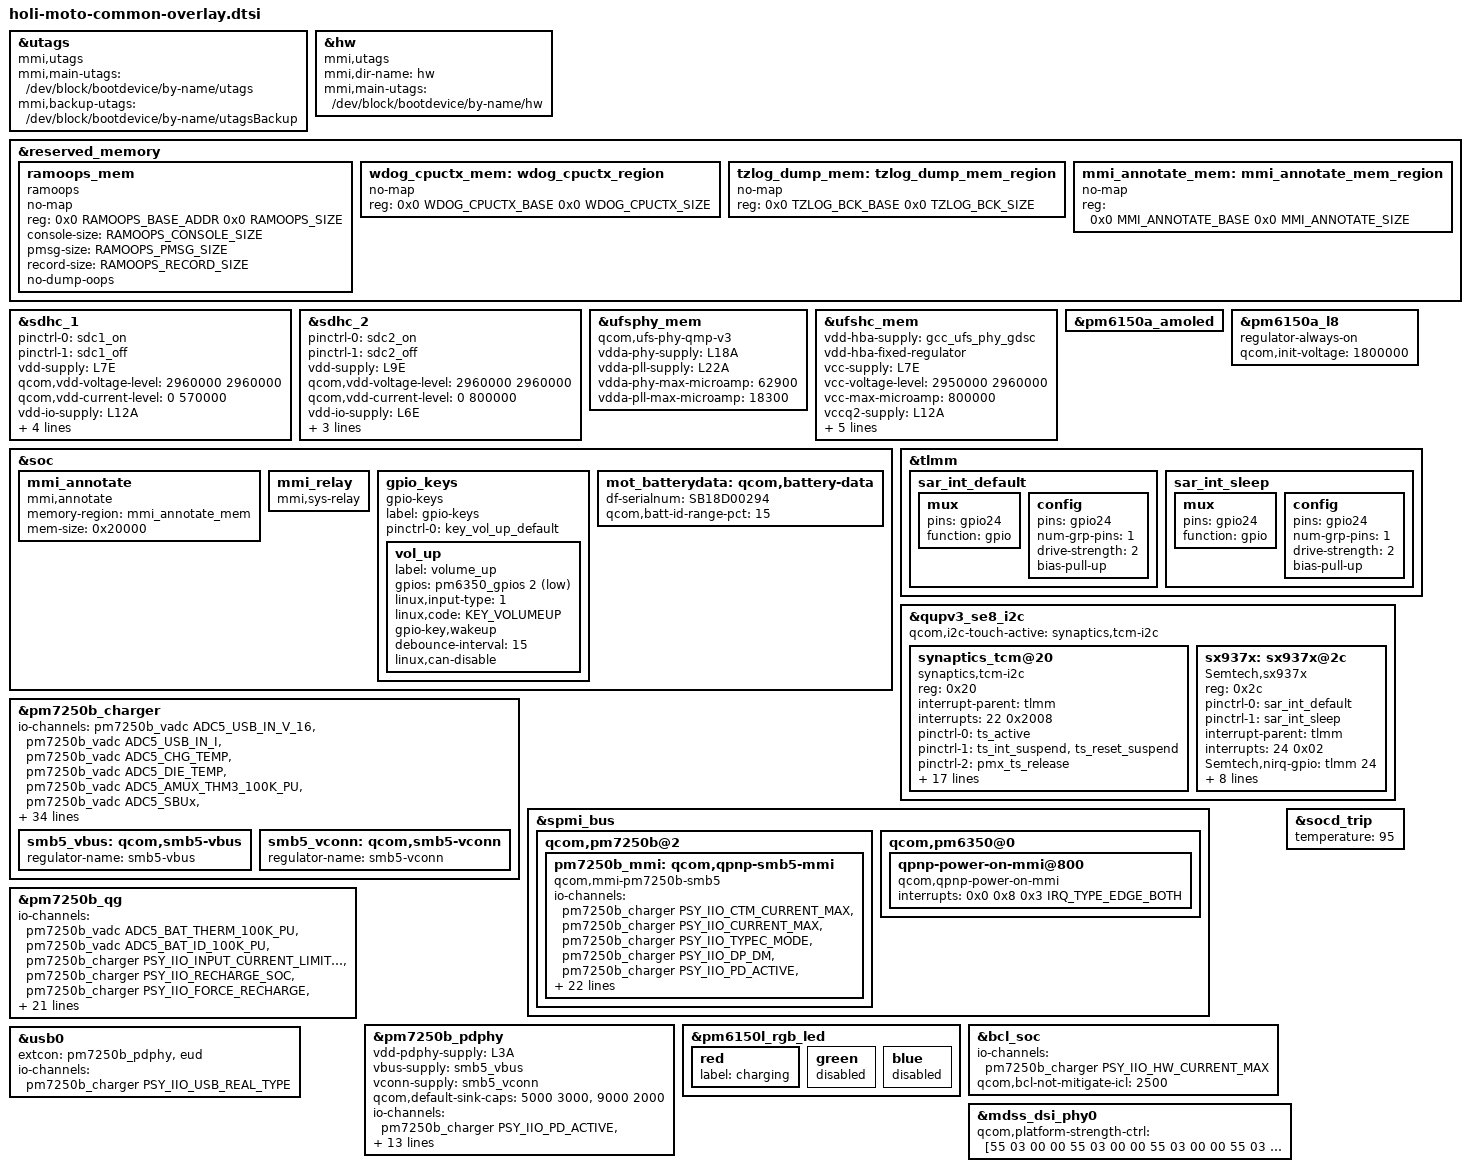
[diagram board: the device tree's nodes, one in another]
/* Copyright (c) 2020, The Linux Foundation. All rights reserved.
 *
 * This program is free software; you can redistribute it and/or modify
 * it under the terms of the GNU General Public License version 2 and
 * only version 2 as published by the Free Software Foundation.
 *
 * This program is distributed in the hope that it will be useful,
 * but WITHOUT ANY WARRANTY; without even the implied warranty of
 * MERCHANTABILITY or FITNESS FOR A PARTICULAR PURPOSE.  See the
 * GNU General Public License for more details.
 */

#include <dt-bindings/gpio/gpio.h>
#include <dt-bindings/input/linux-event-codes.h>
#include "carrier-channel-ids.dtsi"

#include "holi-pmic-overlay.dtsi"
#include "display/holi-sde-display-mtp.dtsi"
#include "holi-thermal-overlay.dtsi"
#include <dt-bindings/iio/qti_power_supply_iio.h>
#include <dt-bindings/moto/moto-mem-reserve.h>

&utags {
	compatible = "mmi,utags";
	mmi,main-utags = "/dev/block/bootdevice/by-name/utags";
	mmi,backup-utags = "/dev/block/bootdevice/by-name/utagsBackup";
};

&hw {
	compatible = "mmi,utags";
	mmi,dir-name = "hw";
	mmi,main-utags = "/dev/block/bootdevice/by-name/hw";
};

&reserved_memory {
	ramoops_mem {
		compatible = "ramoops";
		no-map;
		reg = <0x0 RAMOOPS_BASE_ADDR 0x0 RAMOOPS_SIZE>;
		console-size = <RAMOOPS_CONSOLE_SIZE>;
		pmsg-size = <RAMOOPS_PMSG_SIZE>;
		record-size = <RAMOOPS_RECORD_SIZE>;
		no-dump-oops;
	};

	wdog_cpuctx_mem: wdog_cpuctx_region {
		no-map;
		reg = <0x0 WDOG_CPUCTX_BASE
				0x0 WDOG_CPUCTX_SIZE>;
	};

	tzlog_dump_mem: tzlog_dump_mem_region {
		no-map;
		reg = <0x0  TZLOG_BCK_BASE
				0x0 TZLOG_BCK_SIZE>;
	};

	mmi_annotate_mem: mmi_annotate_mem_region {
		no-map;
		reg = <0x0  MMI_ANNOTATE_BASE
				0x0 MMI_ANNOTATE_SIZE>;
	};
};

&sdhc_1 {
	status = "ok";

	pinctrl-names = "default", "sleep";
	pinctrl-0 = <&sdc1_on>;
	pinctrl-1 = <&sdc1_off>;

	vdd-supply = <&L7E>;
	qcom,vdd-voltage-level = <2960000 2960000>;
	qcom,vdd-current-level = <0 570000>;

	vdd-io-supply = <&L12A>;
	qcom,vdd-io-always-on;
	qcom,vdd-io-lpm-sup;
	qcom,vdd-io-voltage-level = <1800000 1800000>;
	qcom,vdd-io-current-level = <0 325000>;
};

&sdhc_2 {
	status = "ok";

	pinctrl-names = "default", "sleep";
	pinctrl-0 = <&sdc2_on>;
	pinctrl-1 = <&sdc2_off>;

	vdd-supply = <&L9E>;
	qcom,vdd-voltage-level = <2960000 2960000>;
	qcom,vdd-current-level = <0 800000>;

	vdd-io-supply = <&L6E>;
	qcom,vdd-io-voltage-level = <1800000 2960000>;
	qcom,vdd-io-current-level = <0 22000>;

	cd-gpios = <&tlmm 94 GPIO_ACTIVE_LOW>;
};

&ufsphy_mem {
		compatible = "qcom,ufs-phy-qmp-v3";

		vdda-phy-supply = <&L18A>;
		vdda-pll-supply = <&L22A>;
		vdda-phy-max-microamp = <62900>;
		vdda-pll-max-microamp = <18300>;

		status = "ok";
};

&ufshc_mem {
		vdd-hba-supply = <&gcc_ufs_phy_gdsc>;
		vdd-hba-fixed-regulator;

		vcc-supply = <&L7E>;
		vcc-voltage-level = <2950000 2960000>;
		vcc-max-microamp = <800000>;

		vccq2-supply = <&L12A>;
		vccq2-max-microamp = <800000>;
		vccq2-voltage-level = <1800000 1800000>;

		qcom,vddp-ref-clk-supply = <&L22A>;
		qcom,vddp-ref-clk-max-microamp = <100>;

		status = "ok";
};

&soc {
	mmi_annotate {
		compatible = "mmi,annotate";
		memory-region = <&mmi_annotate_mem>;
		mem-size = <0x20000>;
	};

	mmi_relay{
		compatible = "mmi,sys-relay";
	};

	gpio_keys: gpio_keys {
		compatible = "gpio-keys";
		label = "gpio-keys";

		pinctrl-names = "default";
		pinctrl-0 = <&key_vol_up_default>;

		vol_up {
			label = "volume_up";
			gpios = <&pm6350_gpios 2 GPIO_ACTIVE_LOW>;
			linux,input-type = <1>;
			linux,code = <KEY_VOLUMEUP>;
			gpio-key,wakeup;
			debounce-interval = <15>;
			linux,can-disable;
		};
	};

	mot_batterydata: qcom,battery-data {
		df-serialnum = "SB18D00294";
		qcom,batt-id-range-pct = <15>;
		#include "qg-batterydata-md50-amperex-5000mah.dtsi"
	};
};

&pm6150a_amoled {
	status = "ok";
};

&pm6150a_l8 {
	regulator-always-on;
	qcom,init-voltage = <1800000>;
};

&tlmm {
	sar_int_default: sar_int_default {
			mux {
				pins = "gpio24";
				function =  "gpio";
			};
			config {
				pins = "gpio24";
				num-grp-pins = <1>;
				drive-strength = <2>;
				bias-pull-up;
			};
	};

	sar_int_sleep: sar_int_sleep {
			mux {
				pins = "gpio24";
				function =  "gpio";
			};
			config {
				pins = "gpio24";
				num-grp-pins = <1>;
				drive-strength = <2>;
				bias-pull-up;
			};
	};
};

&qupv3_se8_i2c {
	status = "okay";
	qcom,i2c-touch-active="synaptics,tcm-i2c";

	synaptics_tcm@20 {
		compatible = "synaptics,tcm-i2c";
		reg = <0x20>;
		interrupt-parent = <&tlmm>;
		interrupts = <22 0x2008>;
		pinctrl-names = "pmx_ts_active","pmx_ts_suspend",
					"pmx_ts_release";
		pinctrl-0 = <&ts_active>;
		pinctrl-1 = <&ts_int_suspend &ts_reset_suspend>;
		pinctrl-2 = <&pmx_ts_release>;
		vdd-supply = <&L11A>;
		avdd-supply = <&L6A>;
		synaptics,pwr-reg-name = "avdd";
		synaptics,bus-reg-name = "vdd";
		synaptics,irq-gpio = <&tlmm 22 0x2008>;
		synaptics,irq-on-state = <0>;
		synaptics,reset-gpio = <&tlmm 21 0x00>;
		synaptics,reset-on-state = <0>;
		synaptics,reset-active-ms = <20>;
		synaptics,reset-delay-ms = <200>;
		synaptics,power-delay-ms = <200>;
		synaptics,ubl-i2c-addr = <0x20>;
		synaptics,extend_report;
		synaptics,firmware-name = "synaptics_firmware.img";

		panel = <&dsi_rm69299_visionox_amoled_video
			&dsi_rm69299_visionox_amoled_cmd>;
	};

	sx937x:sx937x@2c {
		compatible = "Semtech,sx937x";
		reg = <0x2c>;
		pinctrl-names = "default","sleep";
		pinctrl-0 = <&sar_int_default>;
		pinctrl-1 = <&sar_int_sleep>;
		interrupt-parent = <&tlmm>;
		interrupts = <24 0x02>;
		interrupt-names = "sx937x_irq";
		Semtech,nirq-gpio = <&tlmm 24 0x02>;
		cap_vdd-supply = <&pm6150a_l8>;
		/*use PH4/5/6 as the reference sensor
		set it to 0xff if the ref-phases-x is not used*/
		Semtech,ref-phases-a = <4>;
		Semtech,ref-phases-b = <5>;
		Semtech,ref-phases-c = <6>;
		Semtech,button-flag = <0x0f>;
		Semtech,reg-num = <61>;
		Semtech,reg-init = <
			0x8024  0x7F00 		/*PHEN, Disable all Phases*/
			0x4004  0x74 		/*irq mask*/
			0x8020  0x10 		/*Set scan period*/

			/*set Phase sampling frequency to 65KHz*/
			0x8028  0x876 		/*AFE_PARAM_PH0*/
			0x8034  0x876 		/*AFE_PARAM_PH1*/
			0x8040  0x876 		/*AFE_PARAM_PH2*/
			0x804C  0x876    	/*AFE_PARAM_PH3*/
			0x8058  0x876 		/*AFE_PARAM_PH4*/
			0x8064  0x876 		/*AFE_PARAM_PH5*/
			0x8070  0x876 		/*AFE_PARAM_PH6*/
			/*0x807C  0x876 */	/*AFE_PARAM_PH7*/

			/*set CS3 to hiz, because it used as IRQ pin*/
			0x8030  0xFFD9FF 	/*REG_AFEPH_PH0, CS4, ANT1, Bottom*/
			0x803C  0xBFF9FF 	/*REG_AFEPH_PH1, CS7, ANT2, Top Right*/
			0x8048  0xFFF9FD 	/*REG_AFEPH_PH2, CS0, ANT3, Top Left*/
			0x8054  0xFEF9FF	/*REG_AFEPH_PH3, CS5, ANT4, Top Right side*/
			0x8060  0xF7F9FF 	/*REG_AFEPH_PH4, CS6, ANT1_REF, Bottom*/
			0x806C  0xFFF97F 	/*REG_AFEPH_PH5, CS2, ANT2_REF, Top Right*/
			0x8078  0xFFF9EF 	/*REG_AFEPH_PH6, CS1, ANT3_REF, Top Left*/
			0x8084  0xBFF9FF 	/*REG_AFEPH_PH7, NOT USE*/

			/*Set Phase Proximity Threshold*/
			0x8098  0x00009240		/*prox threshold ph0*/
			0x80B8  0x00008035		/*prox threshold ph1*/
			0x80D8  0x00004343		/*prox threshold ph2*/
			0x80F8  0x00003C3C		/*prox threshold ph3*/
			0x8118  0x00000000		/*prox threshold ph4*/
			0x8138  0x00000000		/*prox threshold ph5*/
			0x8158  0x00000000		/*prox threshold ph6*/
			/*0x8178 0x00000000*/	/*prox threshold ph7*/

			/*Set Useful Filter*/
			0x808C  0x20600019		/*PH0 Filter Setup B, non-detect threshold of USE filter*/
			0x80AC  0x20600019		/*PH1 Filter Setup B, non-detect threshold of USE filter*/
			0x80CC  0x20600019		/*PH2 Filter Setup B, non-detect threshold of USE filter*/
			0x80EC  0x20600019		/*PH3 Filter Setup B, non-detect threshold of USE filter*/
			0x810C  0x20600019		/*PH4 Filter Setup B, non-detect threshold of USE filter*/
			0x812C  0x20600019		/*PH5 Filter Setup B, non-detect threshold of USE filter*/
			0x814C  0x20600019		/*PH6 Filter Setup B, non-detect threshold of USE filter*/
			0x816C  0x20600019		/*PH7 Filter Setup B, non-detect threshold of USE filter*/

			0x8090  0x50D47000
			0x80B0  0x46D87000
			0x80D0  0x46D07000
			0x80F0  0x3CDE7000
			0x8110  0x50D27000
			0x8130  0x50D27000
			0x8150  0x50D27000
			0x8170  0x50D27000

			/*PH0123 raw filter 1/4*/
			0x8088  0x300000
			0x80A8  0x300000
			0x80C8  0x300000
			0x80E8  0x300000

			/*PH456 raw filter 1/64*/
			0x8108  0x600000
			0x8128  0x600000
			0x8148  0x600000

			/*Set Reference Phase*/
			0x8188  0x8000014		/*Reference Correction Setup B ENG1*/
			0x818C  0x0				/*Reference Correction Setup B ENG2*/
			0x8190  0x0				/*Reference Correction Setup B ENG3*/
			0x8194  0x0				/*Reference Correction Setup B ENG4*/

			/*Set Reference Correction*/
			0x80A0  0x222200E1      /*Reference Correction Setup A PH0*/
			0x80C0  0x0				/*Reference Correction Setup A PH1*/
			0x80E0  0x0				/*Reference Correction Setup A PH2*/
			0x8100  0x0				/*Reference Correction Setup A PH3*/
			0x8120  0x0				/*Reference Correction Setup A PH4*/
			0x8140  0x0				/*Reference Correction Setup A PH5*/
			0x8160  0x0				/*Reference Correction Setup A PH6*/
			0x8180  0x0				/*Reference Correction Setup A PH7*/

			0x8024  0x7F7F 	/*PHEN, Enable PH0~PH6*/
		>;

		status = "ok";
	};
};

&pm7250b_charger {
	status = "ok";
	#io-channel-cells = <1>;
	io-channels = <&pm7250b_vadc ADC5_USB_IN_V_16>,
		      <&pm7250b_vadc ADC5_USB_IN_I>,
		      <&pm7250b_vadc ADC5_CHG_TEMP>,
		      <&pm7250b_vadc ADC5_DIE_TEMP>,
		      <&pm7250b_vadc ADC5_AMUX_THM3_100K_PU>,
		      <&pm7250b_vadc ADC5_SBUx>,
		      <&pm7250b_vadc ADC5_VPH_PWR>,
		      <&pm7250b_vadc ADC5_AMUX_THM1_100K_PU>,
		      <&pm7250b_qg PSY_IIO_RESISTANCE_ID>,
		      <&pm7250b_qg PSY_IIO_VOLTAGE_NOW>,
		      <&pm7250b_qg PSY_IIO_TEMP>,
		      <&pm7250b_qg PSY_IIO_CAPACITY>,
		      <&pm7250b_qg PSY_IIO_VOLTAGE_OCV>,
		      <&pm7250b_qg PSY_IIO_VOLTAGE_AVG>,
		      <&pm7250b_qg PSY_IIO_DEBUG_BATTERY>,
		      <&pm7250b_qg PSY_IIO_REAL_CAPACITY>,
		      <&pm7250b_qg PSY_IIO_CC_SOC>,
		      <&pm7250b_qg PSY_IIO_CURRENT_NOW>,
		      <&pm7250b_qg PSY_IIO_VOLTAGE_MAX>,
		      <&pm7250b_qg PSY_IIO_CHARGE_FULL>,
		      <&pm7250b_qg PSY_IIO_CHARGE_COUNTER>,
		      <&pm7250b_qg PSY_IIO_CYCLE_COUNT>,
		      <&pm7250b_qg PSY_IIO_CHARGE_FULL_DESIGN>,
		      <&pm7250b_qg PSY_IIO_TIME_TO_FULL_NOW>;
	io-channel-names = "usb_in_voltage",
			   "usb_in_current",
			   "chg_temp",
			   "die_temp",
			   "conn_temp",
			   "sbux_res",
			   "vph_voltage",
			   "skin_temp",
			   "resistance_id",
			   "voltage_now",
			   "temp",
			   "capacity",
			   "voltage_ocv",
			   "voltage_avg",
			   "debug_battery",
			   "real_capacity",
			   "cc_soc",
			   "current_now",
			   "voltage_max",
			   "charge_full",
			   "charge_counter",
			   "cycle_count",
			   "charge_full_design",
			   "time_to_full_now";
	qcom,battery-data = <&mot_batterydata>;
	qcom,sec-charger-config = <0>;
	qcom,auto-recharge-soc = <98>;
	qcom,charger-temp-max = <800>;
	qcom,smb-temp-max = <800>;
	qcom,suspend-input-on-debug-batt;
	qcom,hvdcp3-standalone-config;
	qcom,fcc-max-ua = <4000000>;
	qcom,fv-max-uv = <4450000>;
	qcom,usb-icl-ua = <3000000>;
	qcom,hvdcp2-max-icl-ua = <1500000>;
	qcom,thermal-mitigation = <4000000 3500000
			3000000 2500000
			2000000 1500000
			1200000 900000
			600000 300000>;
	qcom,pd-voltage-max-uv = <9000000>;
	qcom,usbpd-phandle = <&pm7250b_pdphy>;
};

&spmi_bus {
	qcom,pm7250b@2 {
		pm7250b_mmi: qcom,qpnp-smb5-mmi {
			status = "ok";
			compatible = "qcom,mmi-pm7250b-smb5";
			#io-channel-cells = <1>;
			io-channels = <&pm7250b_charger PSY_IIO_CTM_CURRENT_MAX>,
				      <&pm7250b_charger PSY_IIO_CURRENT_MAX>,
				      <&pm7250b_charger PSY_IIO_TYPEC_MODE>,
				      <&pm7250b_charger PSY_IIO_DP_DM>,
				      <&pm7250b_charger PSY_IIO_PD_ACTIVE>,
				      <&pm7250b_charger PSY_IIO_USB_REAL_TYPE>,
				      <&pm7250b_charger PSY_IIO_HW_CURRENT_MAX>,
				      <&pm7250b_charger PSY_IIO_USB_INPUT_CURRENT_SETTLED>,
				      <&pm7250b_charger PSY_IIO_RERUN_AICL>,
				      <&pm7250b_charger PSY_IIO_SW_JEITA_ENABLED>,
				      <&pm7250b_charger PSY_IIO_PD_CURRENT_MAX>,
				      <&pm7250b_qg PSY_IIO_VOLTAGE_NOW>,
				      <&pm7250b_qg PSY_IIO_CURRENT_NOW>,
				      <&pm7250b_qg PSY_IIO_TEMP>,
				      <&pm7250b_qg PSY_IIO_CAPACITY>,
				      <&pm7250b_qg PSY_IIO_CHARGE_FULL>,
				      <&pm7250b_qg PSY_IIO_BATT_FULL_CURRENT>,
				      <&pm7250b_qg PSY_IIO_CHARGE_FULL_DESIGN>;
			io-channel-names = "usb_ctm_current_max",
					   "main_current_max",
					   "usb_typec_mode",
					   "battery_dp_dm",
					   "usb_pd_active",
					   "usb_real_type",
					   "usb_hw_current_max",
					   "usb_input_current_settled",
					   "battery_rerun_aicl",
					   "battery_sw_jeita_enabled",
					   "usb_pd_current_max",
					   "voltage_now",
					   "current_now",
					   "temp",
					   "capacity",
					   "charge_full",
					   "batt_full_current",
					   "charge_full_design";
			qcom,enable-charging-limit;
			qcom,upper-limit-capacity = <65>;
			qcom,lower-limit-capacity = <60>;
			qcom,mmi-temp-zones = <0 4200 970 0>,
						<10 4200 2500 970>,
						<15 0 2500 2500>,
						<45 0 4000 4000>,
						<60 4200 2500 0>;
			qcom,iterm-ma = <242>;
			qcom,force-hvdcp-5v;
			qcom,usbpd-phandle = <&pm7250b_pdphy>;
		};
	};

	qcom,pm6350@0 {
		qpnp-power-on-mmi@800 {
			compatible = "qcom,qpnp-power-on-mmi";
			interrupts = <0x0 0x8 0x3 IRQ_TYPE_EDGE_BOTH>;
			interrupt-names = "kpdpwr-bark";
		};
	};
};

&pm7250b_qg {
	status = "ok";
	#io-channel-cells = <1>;
	io-channels = <&pm7250b_vadc ADC5_BAT_THERM_100K_PU>,
		      <&pm7250b_vadc ADC5_BAT_ID_100K_PU>,
		      <&pm7250b_charger PSY_IIO_INPUT_CURRENT_LIMITED>,
		      <&pm7250b_charger PSY_IIO_RECHARGE_SOC>,
		      <&pm7250b_charger PSY_IIO_FORCE_RECHARGE>,
		      <&pm7250b_charger PSY_IIO_CHARGE_DONE>;
	io-channel-names = "batt-therm",
			   "batt-id",
			   "input_current_limited",
			   "recharge_soc",
			   "force_recharge",
			   "charge_done";
	qcom,battery-data = <&mot_batterydata>;
	qcom,qg-iterm-ma = <150>;
	qcom,hold-soc-while-full;
	qcom,linearize-soc;
	qcom,cl-feedback-on;
        qcom,cl-min-start-soc = <0>;
        qcom,cl-max-start-soc = <5>;
        qcom,cl-min-temp = <150>;
        qcom,cl-max-temp = <450>;
        qcom,cl-max-increment = <5>;
        qcom,cl-max-decrement = <10>;
        qcom,cl-min-limit = <200>;
        qcom,cl-max-limit = <30>;
	qcom,tcss-enable;
	qcom,fvss-enable;
	qcom,fvss-vbatt-mv = <3300>;
	qcom,bass-enable;
	qcom,use-cp-iin-sns;
	qcom,s3-entry-ibat-ua = <35000>;
	qcom,s3-exit-ibat-ua = <50000>;
};

&pm7250b_charger {
	dpdm-supply = <&qusb_phy0>;

	smb5_vbus: qcom,smb5-vbus {
		regulator-name = "smb5-vbus";
	};

	smb5_vconn: qcom,smb5-vconn {
		regulator-name = "smb5-vconn";
	};
};

&pm7250b_pdphy {
	vdd-pdphy-supply = <&L3A>;
	vbus-supply = <&smb5_vbus>;
	vconn-supply = <&smb5_vconn>;
	qcom,default-sink-caps = <5000 3000>, /*5V @ 3A*/
				 <9000 2000>; /*9V @ 2A*/

	#io-channel-cells = <1>;
	io-channels = <&pm7250b_charger PSY_IIO_PD_ACTIVE>,
		      <&pm7250b_charger PSY_IIO_TYPEC_CC_ORIENTATION>,
		      <&pm7250b_charger PSY_IIO_CONNECTOR_TYPE>,
		      <&pm7250b_charger PSY_IIO_TYPEC_POWER_ROLE>,
		      <&pm7250b_charger PSY_IIO_PD_USB_SUSPEND_SUPPORTED>,
		      <&pm7250b_charger PSY_IIO_TYPEC_SRC_RP>,
		      <&pm7250b_charger PSY_IIO_PD_IN_HARD_RESET>,
		      <&pm7250b_charger PSY_IIO_PD_CURRENT_MAX>,
		      <&pm7250b_charger PSY_IIO_PR_SWAP>,
		      <&pm7250b_charger PSY_IIO_PD_VOLTAGE_MIN>,
		      <&pm7250b_charger PSY_IIO_PD_VOLTAGE_MAX>,
		      <&pm7250b_charger PSY_IIO_USB_REAL_TYPE>,
		      <&pm7250b_charger PSY_IIO_TYPEC_MODE>,
		      <&pm7250b_charger PSY_IIO_PE_START>;
	io-channel-names = "pd_active",
			   "typec_cc_orientation",
			   "connector_type",
			   "typec_power_role",
			   "pd_usb_suspend_supported",
			   "typec_src_rp",
			   "pd_in_hard_reset",
			   "pr_current_max",
			   "pr_swap",
			   "pd_voltage_min",
			   "pd_voltage_max",
			   "real_type",
			   "typec_mode",
			   "pe_start";
};

&pm6150l_rgb_led {
	red {
		label = "charging";
	};

	green {
		status = "disabled";
	};

	blue {
		status = "disabled";
	};
};

&bcl_soc {
	io-channels = <&pm7250b_charger PSY_IIO_HW_CURRENT_MAX>;
	io-channel-names = "usb_hw_current_max";
	qcom,bcl-not-mitigate-icl = <2500>;
};

&socd_trip {
       temperature = <95>;
};

&usb0 {
	extcon = <&pm7250b_pdphy>, <&eud>;
	#io-channel-cells = <1>;
	io-channels= <&pm7250b_charger PSY_IIO_USB_REAL_TYPE>;
	io-channel-names = "chg_type";
};

&ufshc_mem {
	spm-level = <3>;
};

&mdss_dsi_phy0 {
	qcom,platform-strength-ctrl = [55 03 00 00
				55 03 00 00
				55 03 00 00
				55 03 00 00
				55 00 00 00];
};
